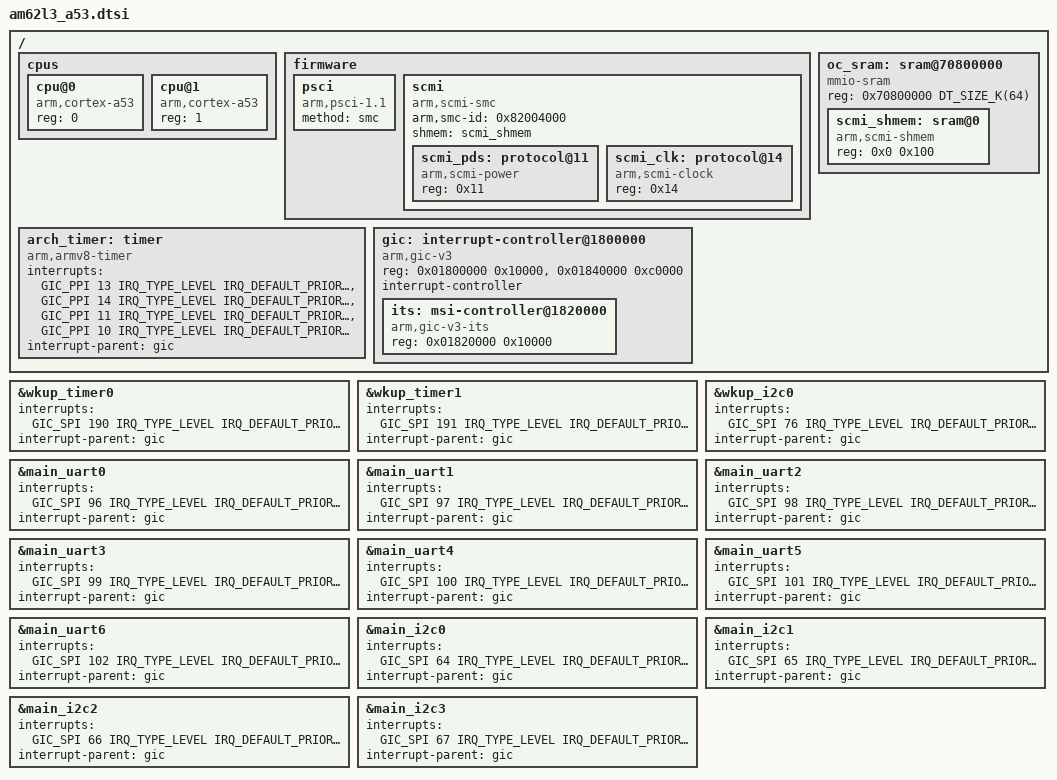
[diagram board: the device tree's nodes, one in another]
/*
 * Copyright (C) 2025 Texas Instruments Incorporated - https://www.ti.com/
 *
 * SPDX-License-Identifier: Apache-2.0
 */

#include <mem.h>
#include <freq.h>
#include <arm64/armv8-a.dtsi>
#include <zephyr/dt-bindings/interrupt-controller/arm-gic.h>
#include <zephyr/dt-bindings/pinctrl/ti-k3-pinctrl.h>
#include <zephyr/dt-bindings/gpio/gpio.h>
#include <ti/am62l-main.dtsi>
#include <ti/am62l-wakeup.dtsi>

/ {
	#address-cells = <1>;
	#size-cells = <1>;

	cpus {
		#address-cells = <1>;
		#size-cells = <0>;

		cpu@0 {
			device_type = "cpu";
			compatible = "arm,cortex-a53";
			reg = <0>;
		};

		cpu@1 {
			device_type = "cpu";
			compatible = "arm,cortex-a53";
			reg = <1>;
		};
	};

	firmware {
		psci: psci {
			compatible = "arm,psci-1.1";
			method = "smc";
		};

		scmi {
			compatible = "arm,scmi-smc";
			arm,smc-id = <0x82004000>;
			shmem = <&scmi_shmem>;

			#address-cells = <1>;
			#size-cells = <0>;

			scmi_pds: protocol@11 {
				compatible = "arm,scmi-power";
				reg = <0x11>;
				#power-domain-cells = <1>;
			};

			scmi_clk: protocol@14 {
				compatible = "arm,scmi-clock";
				reg = <0x14>;
				#clock-cells = <1>;
			};
		};
	};

	oc_sram: sram@70800000 {
		compatible = "mmio-sram";
		reg = <0x70800000 DT_SIZE_K(64)>;
		ranges = <0x0 0x70800000 0x10000>;
		#address-cells = <1>;
		#size-cells = <1>;

		scmi_shmem: sram@0 {
			compatible = "arm,scmi-shmem";
			reg = <0x0 0x100>;
		};
	};

	arch_timer: timer {
		compatible = "arm,armv8-timer";
		interrupts = <GIC_PPI 13 IRQ_TYPE_LEVEL IRQ_DEFAULT_PRIORITY>,
			     <GIC_PPI 14 IRQ_TYPE_LEVEL IRQ_DEFAULT_PRIORITY>,
			     <GIC_PPI 11 IRQ_TYPE_LEVEL IRQ_DEFAULT_PRIORITY>,
			     <GIC_PPI 10 IRQ_TYPE_LEVEL IRQ_DEFAULT_PRIORITY>;
		interrupt-parent = <&gic>;
	};

	gic: interrupt-controller@1800000 {
		compatible = "arm,gic-v3", "arm,gic";
		reg = <0x01800000 0x10000>, /* GICD */
		      <0x01840000 0xc0000>; /* GICR */
		interrupt-controller;
		#interrupt-cells = <4>;
		#address-cells = <1>;
		#size-cells = <1>;
		status = "okay";

		its: msi-controller@1820000 {
			compatible = "arm,gic-v3-its";
			reg = <0x01820000 0x10000>;
			status = "okay";
		};
	};
};

&wkup_timer0 {
	interrupts = <GIC_SPI 190 IRQ_TYPE_LEVEL IRQ_DEFAULT_PRIORITY>;
	interrupt-parent = <&gic>;
};

&wkup_timer1 {
	interrupts = <GIC_SPI 191 IRQ_TYPE_LEVEL IRQ_DEFAULT_PRIORITY>;
	interrupt-parent = <&gic>;
};

&wkup_i2c0 {
	interrupts = <GIC_SPI 76 IRQ_TYPE_LEVEL IRQ_DEFAULT_PRIORITY>;
	interrupt-parent = <&gic>;
};

&main_uart0 {
	interrupts = <GIC_SPI 96 IRQ_TYPE_LEVEL IRQ_DEFAULT_PRIORITY>;
	interrupt-parent = <&gic>;
};

&main_uart1 {
	interrupts = <GIC_SPI 97 IRQ_TYPE_LEVEL IRQ_DEFAULT_PRIORITY>;
	interrupt-parent = <&gic>;
};

&main_uart2 {
	interrupts = <GIC_SPI 98 IRQ_TYPE_LEVEL IRQ_DEFAULT_PRIORITY>;
	interrupt-parent = <&gic>;
};

&main_uart3 {
	interrupts = <GIC_SPI 99 IRQ_TYPE_LEVEL IRQ_DEFAULT_PRIORITY>;
	interrupt-parent = <&gic>;
};

&main_uart4 {
	interrupts = <GIC_SPI 100 IRQ_TYPE_LEVEL IRQ_DEFAULT_PRIORITY>;
	interrupt-parent = <&gic>;
};

&main_uart5 {
	interrupts = <GIC_SPI 101 IRQ_TYPE_LEVEL IRQ_DEFAULT_PRIORITY>;
	interrupt-parent = <&gic>;
};

&main_uart6 {
	interrupts = <GIC_SPI 102 IRQ_TYPE_LEVEL IRQ_DEFAULT_PRIORITY>;
	interrupt-parent = <&gic>;
};

&main_i2c0 {
	interrupts = <GIC_SPI 64 IRQ_TYPE_LEVEL IRQ_DEFAULT_PRIORITY>;
	interrupt-parent = <&gic>;
};

&main_i2c1 {
	interrupts = <GIC_SPI 65 IRQ_TYPE_LEVEL IRQ_DEFAULT_PRIORITY>;
	interrupt-parent = <&gic>;
};

&main_i2c2 {
	interrupts = <GIC_SPI 66 IRQ_TYPE_LEVEL IRQ_DEFAULT_PRIORITY>;
	interrupt-parent = <&gic>;
};

&main_i2c3 {
	interrupts = <GIC_SPI 67 IRQ_TYPE_LEVEL IRQ_DEFAULT_PRIORITY>;
	interrupt-parent = <&gic>;
};
